# GD32H77x_78x register map
File version: 1.0
CPU: CM7 r1p2, little endian, MPU, FPU, 4 interrupt priority bits
Registers are 32-bit, read-write, reset 0x0 unless marked. A register's access mark holds for its fields unless they carry their own. Offsets are from the block's base; [hi:lo] are bit positions.

## CPDM_SDIO0 — SDIO0 clock phase delay module
Base 0x52008000
Same registers: CPDM_SDIO1 0x48022800, CPDM_OSPI0 0x52006000, CPDM_OSPI1 0x5200B000
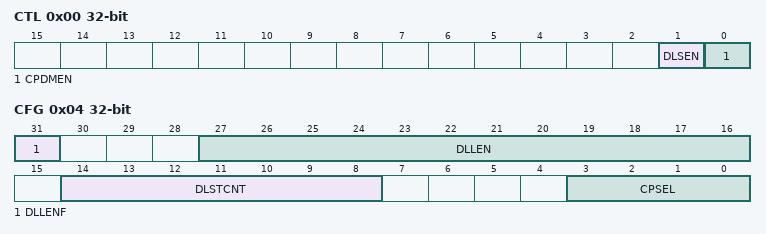
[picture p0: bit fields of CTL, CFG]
0x00 CTL — Control register
  [1] DLSEN — CPDM delay line sample module enable bit
  [0] CPDMEN — CPDM enable bit
0x04 CFG access per field — Configuration register
  [31] DLLENF ro — Valid mark of delay line length
  [27:16] DLLEN ro — Delay line length
  [14:8] DLSTCNT rw — Defines a delay step count for a unit delay UNIT
  [3:0] CPSEL rw — Select the phase of the output clock

## CRC — CRC calculation unit
Base 0x58024C00
0x00 DATA reset 0xFFFFFFFF
  [31:0] DATA — CRC calculation result bits
0x04 FDATA — Free data register
  [7:0] FDATA — Free data register bits
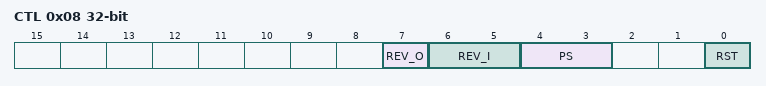
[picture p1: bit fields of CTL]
0x08 CTL — Control register
  [7] REV_O — Reverse output data value in bit order
  [6:5] REV_I — Reverse type for input date
  [4:3] PS — Size of polynomial
  [0] RST — Software writes and reads
0x10 IDATA reset 0xFFFFFFFF — Initialization data register
  [31:0] IDATA — Configurable initial CRC data value
0x14 POLY reset 0x4C11DB7 — Polynomial register
  [31:0] POLY — User configurable polynomial value

## CTC — Clock trim controller
Base 0x40008400
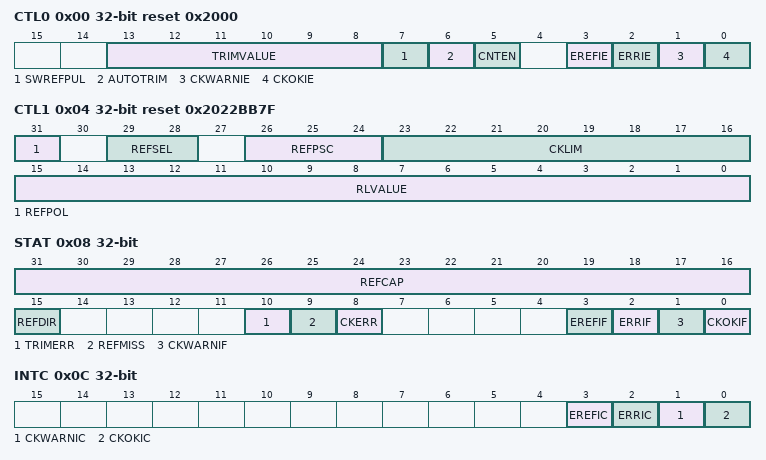
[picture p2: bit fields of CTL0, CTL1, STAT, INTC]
0x00 CTL0 access per field reset 0x2000 — Control register 0
  [13:8] TRIMVALUE rw — IRC48M trim value
  [7] SWREFPUL wo — Software reference source sync pulse
  [6] AUTOTRIM rw — Hardware automatically trim mode
  [5] CNTEN rw — CTC counter enable
  [3] EREFIE rw — EREFIF interrupt enable
  [2] ERRIE rw — Error (ERRIF) interrupt enable
  [1] CKWARNIE rw — Clock trim warning (CKWARNIF) interrupt enable
  [0] CKOKIE rw — Clock trim OK (CKOKIF) interrupt enable
0x04 CTL1 reset 0x2022BB7F — Control register 1
  [31] REFPOL — Reference signal source polarity
  [29:28] REFSEL — Reference signal source selection
  [26:24] REFPSC — Reference signal source prescaler
  [23:16] CKLIM — Clock trim base limit value
  [15:0] RLVALUE — CTC counter reload value
0x08 STAT ro — Status register
  [31:16] REFCAP — CTC counter capture when reference sync pulse
  [15] REFDIR — CTC trim counter direction when reference sync pulse
  [10] TRIMERR — Trim value error bit
  [9] REFMISS — Reference sync pulse miss
  [8] CKERR — Clock trim error bit
  [3] EREFIF — Expect reference interrupt flag
  [2] ERRIF — Error interrupt flag
  [1] CKWARNIF — Clock trim warning interrupt flag
  [0] CKOKIF — Clock trim OK interrupt flag
0x0C INTC wo — Interrupt clear register
  [3] EREFIC — EREFIF interrupt clear bit
  [2] ERRIC — ERRIF interrupt clear bit
  [1] CKWARNIC — CKWARNIF interrupt clear bit
  [0] CKOKIC — CKOKIF interrupt clear bit

## DAC0 — Digital-to-analog converter
Base 0x40007400
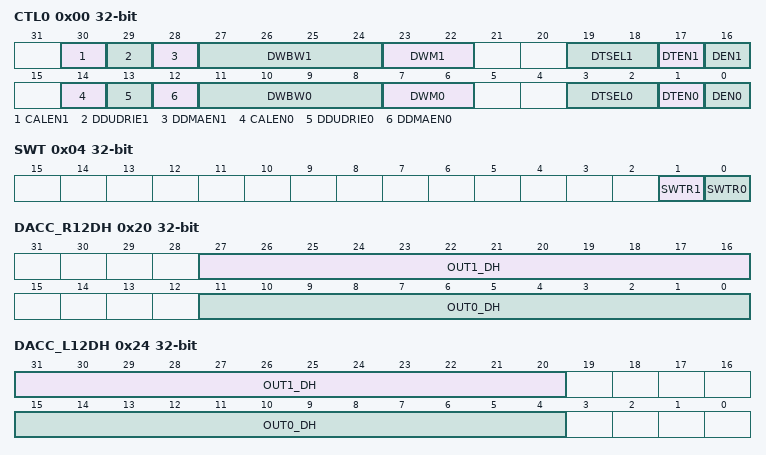
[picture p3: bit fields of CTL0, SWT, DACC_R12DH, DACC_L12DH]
0x00 CTL0 — Control register 0
  [30] CALEN1 — DAC_OUT1 calibration enable
  [29] DDUDRIE1 — DAC_OUT1 DMA underrun interrupt enable
  [28] DDMAEN1 — DAC_OUT1 DMA enable
  [27:24] DWBW1 — DAC_OUT1 noise wave bit width
  [23:22] DWM1 — DAC_OUT1 noise wave mode
  [19:18] DTSEL1 — DAC_OUT1 trigger selection
  [17] DTEN1 — DAC_OUT1 trigger enable
  [16] DEN1 — DAC_OUT1 enable
  [14] CALEN0 — DAC_OUT0 calibration enable
  [13] DDUDRIE0 — DAC_OUT0 DMA underrun interrupt enable
  [12] DDMAEN0 — DAC_OUT0 DMA enable
  [11:8] DWBW0 — DAC_OUT0 noise wave bit width
  [7:6] DWM0 — DAC_OUT0 noise wave mode
  [3:2] DTSEL0 — DAC_OUT0 trigger selection
  [1] DTEN0 — DAC_OUT0 trigger enable
  [0] DEN0 — DAC_OUT0 enable
0x04 SWT wo — Software trigger register
  [1] SWTR1 — DAC_OUT1 software trigger, cleared by hardware
  [0] SWTR0 — DAC_OUT0 software trigger, cleared by hardware
0x08 OUT0_R12DH — DAC_OUT0 12-bit right-aligned data holding register
  [11:0] OUT0_DH — DAC_OUT0 12-bit right-aligned data
0x0C OUT0_L12DH — DAC_OUT0 12-bit left-aligned data holding register
  [15:4] OUT0_DH — DAC_OUT0 12-bit left-aligned data
0x10 OUT0_R8DH — DAC_OUT0 8-bit right-aligned data holding register
  [7:0] OUT0_DH — DAC_OUT0 8-bit right-aligned data
0x14 OUT1_R12DH — DAC_OUT1 12-bit right-aligned data holding register
  [11:0] OUT1_DH — DAC_OUT1 12-bit right-aligned data
0x18 OUT1_L12DH — DAC_OUT1 12-bit left-aligned data holding register
  [15:4] OUT1_DH — OUT1_DH[11:0]
0x1C OUT1_R8DH — DAC_OUT1 8-bit right-aligned data holding register
  [7:0] OUT1_DH — DAC_OUT1 8-bit right-aligned data
0x20 DACC_R12DH — DAC concurrent mode 12-bit right-aligned data holding register
  [27:16] OUT1_DH — DAC_OUT1 12-bit right-aligned data
  [11:0] OUT0_DH — DAC_OUT0 12-bit right-aligned data
0x24 DACC_L12DH — DAC concurrent mode 12-bit left-aligned data holding register
  [31:20] OUT1_DH — DAC_OUT1 12-bit left-aligned data
  [15:4] OUT0_DH — DAC_OUT0 12-bit left-aligned data
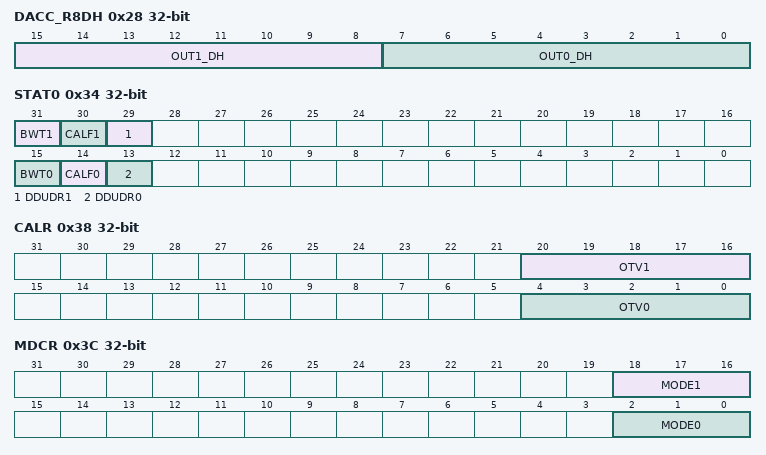
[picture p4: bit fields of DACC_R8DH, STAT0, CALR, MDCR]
0x28 DACC_R8DH — DAC concurrent mode 8-bit right-aligned data holding register
  [15:8] OUT1_DH — DAC_OUT1 8-bit right-aligned data
  [7:0] OUT0_DH — DAC_OUT0 8-bit right-aligned data
0x2C OUT0_DO ro — DAC_OUT0 data output register
  [11:0] OUT0_DO — DAC_OUT0 data output
0x30 OUT1_DO ro — DAC_OUT1 data output register
  [11:0] OUT1_DO — DAC_OUT1 data output
0x34 STAT0 ro — DAC Status register 0
  [31] BWT1 — This bit will be set after sample and keep mode enable
  [30] CALF1 — DAC_OUT1 calibration offset flag
  [29] DDUDR1 — DAC_OUT1 DMA underrun flag, set by hardware, cleared by software write 1
  [15] BWT0 — This bit will be set after sample and keep mode enable
  [14] CALF0 — DAC_OUT0 calibration offset flag
  [13] DDUDR0 — DAC_OUT0 DMA underrun flag, set by hardware, cleared by software write 1
0x38 CALR — DAC calibration Register 1
  [20:16] OTV1 — DAC_OUT1 offset calibration value
  [4:0] OTV0 — DAC_OUT0 offset calibration value
0x3C MDCR — DAC mode control Register 1
  [18:16] MODE1 — DAC OUT1 mode.
  [2:0] MODE0 — DAC OUT0 mode.
0x40 SKSTR0 — DAC sample and keep sample time Register 0
  [9:0] TSAMP0 — DAC_OUT0 sample time.
0x44 SKSTR1 — DAC sample and keep sample time Register 1
  [9:0] TSAMP1 — DAC_OUT refresh time (only valid in Sample and hold mode)
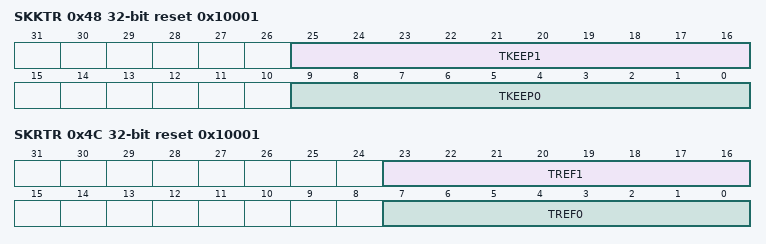
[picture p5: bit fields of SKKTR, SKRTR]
0x48 SKKTR reset 0x10001 — DAC sample and keep keep time Register
  [25:16] TKEEP1 — DAC_OUT1 keep time
  [9:0] TKEEP0 — DAC_OUT0 keep time
0x4C SKRTR reset 0x10001 — DAC sample and keep refresh time Register
  [23:16] TREF1 — DAC_OUT1 refresh time
  [7:0] TREF0 — DAC_OUT0 refresh time
